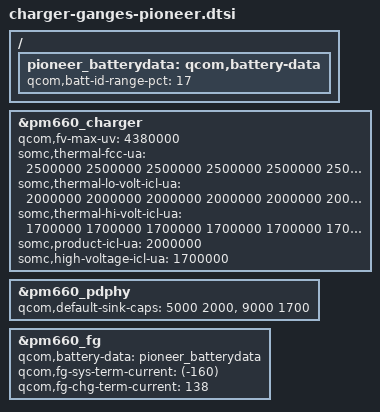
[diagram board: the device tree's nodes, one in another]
/* Copyright (c) 2015-2017, The Linux Foundation. All rights reserved.
 *
 * This program is free software; you can redistribute it and/or modify
 * it under the terms of the GNU General Public License version 2 and
 * only version 2 as published by the Free Software Foundation.
 *
 * This program is distributed in the hope that it will be useful,
 * but WITHOUT ANY WARRANTY; without even the implied warranty of
 * MERCHANTABILITY or FITNESS FOR A PARTICULAR PURPOSE.  See the
 * GNU General Public License for more details.
 */

/ {
        pioneer_batterydata: qcom,battery-data {
                qcom,batt-id-range-pct = <17>;
                #include "fg-gen3-batterydata-pioneer-send-4380mv-3200mah.dtsi"
                #include "fg-gen3-batterydata-pioneer-send-4335mv-3200mah.dtsi"
                #include "fg-gen3-batterydata-pioneer-send-4297mv-3200mah.dtsi"
                #include "fg-gen3-batterydata-pioneer-send-4245mv-3200mah.dtsi"
                #include "fg-gen3-batterydata-pioneer-tdk-4380mv-3200mah.dtsi"
                #include "fg-gen3-batterydata-pioneer-tdk-4335mv-3200mah.dtsi"
                #include "fg-gen3-batterydata-pioneer-tdk-4297mv-3200mah.dtsi"
                #include "fg-gen3-batterydata-pioneer-tdk-4245mv-3200mah.dtsi"
        };
};

&pm660_charger {
	qcom,fv-max-uv = <4380000>;
        somc,thermal-fcc-ua = <2500000 2500000 2500000
                                2500000 2500000 2500000
                                2500000 2500000 2500000
                                2500000 2500000 2500000
                                2500000 2500000 2500000>;
        somc,thermal-lo-volt-icl-ua = <2000000 2000000 2000000
                                        2000000 2000000 2000000
                                        2000000 2000000 2000000
                                        2000000 2000000 2000000
                                        2000000 2000000 2000000>;
        somc,thermal-hi-volt-icl-ua = <1700000 1700000 1700000
                                        1700000 1700000 1700000
                                        1700000 1700000 1700000
                                        1700000 1700000 1700000
                                        1700000 1700000 1700000>;
        somc,product-icl-ua = <2000000>;
        somc,high-voltage-icl-ua = <1700000>;
};

&pm660_pdphy {
	qcom,default-sink-caps = <5000 2000>, /* 5V @ 2A */
				 <9000 1700>; /* 9V @ 1.7A */
};

&pm660_fg {
	qcom,battery-data = <&pioneer_batterydata>;
	qcom,fg-sys-term-current = <(-160)>;
	qcom,fg-chg-term-current = <138>;
};
